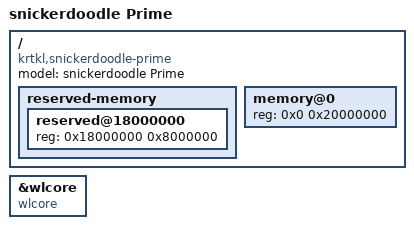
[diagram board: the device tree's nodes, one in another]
/**
 * Copyright (c) 2016 krtkl inc.
 *
 * snickerdoodle prime base device tree source
 *
 * This program is free software; you can redistribute it and/or modify it
 * under the terms of the GNU General Public License version 2 as published by
 * the Free Software Foundation.
 */

/include/ "snickerdoodle.dtsi"
/ {
        model = "snickerdoodle Prime";
        compatible = "krtkl,snickerdoodle-prime", "krtkl,snickerdoodle", "xlnx,zynq-7000";

	reserved-memory {
		#address-cells = <1>;
		#size-cells = <1>;
		ranges;

		reserved@18000000 {
			reg = <0x18000000 0x8000000>;
		};
	};

	memory@0 {
		device_type = "memory";
		reg = <0x0 0x20000000>;
	};
};

&wlcore {
	compatible = "wlcore", "ti,wl1801";
};
